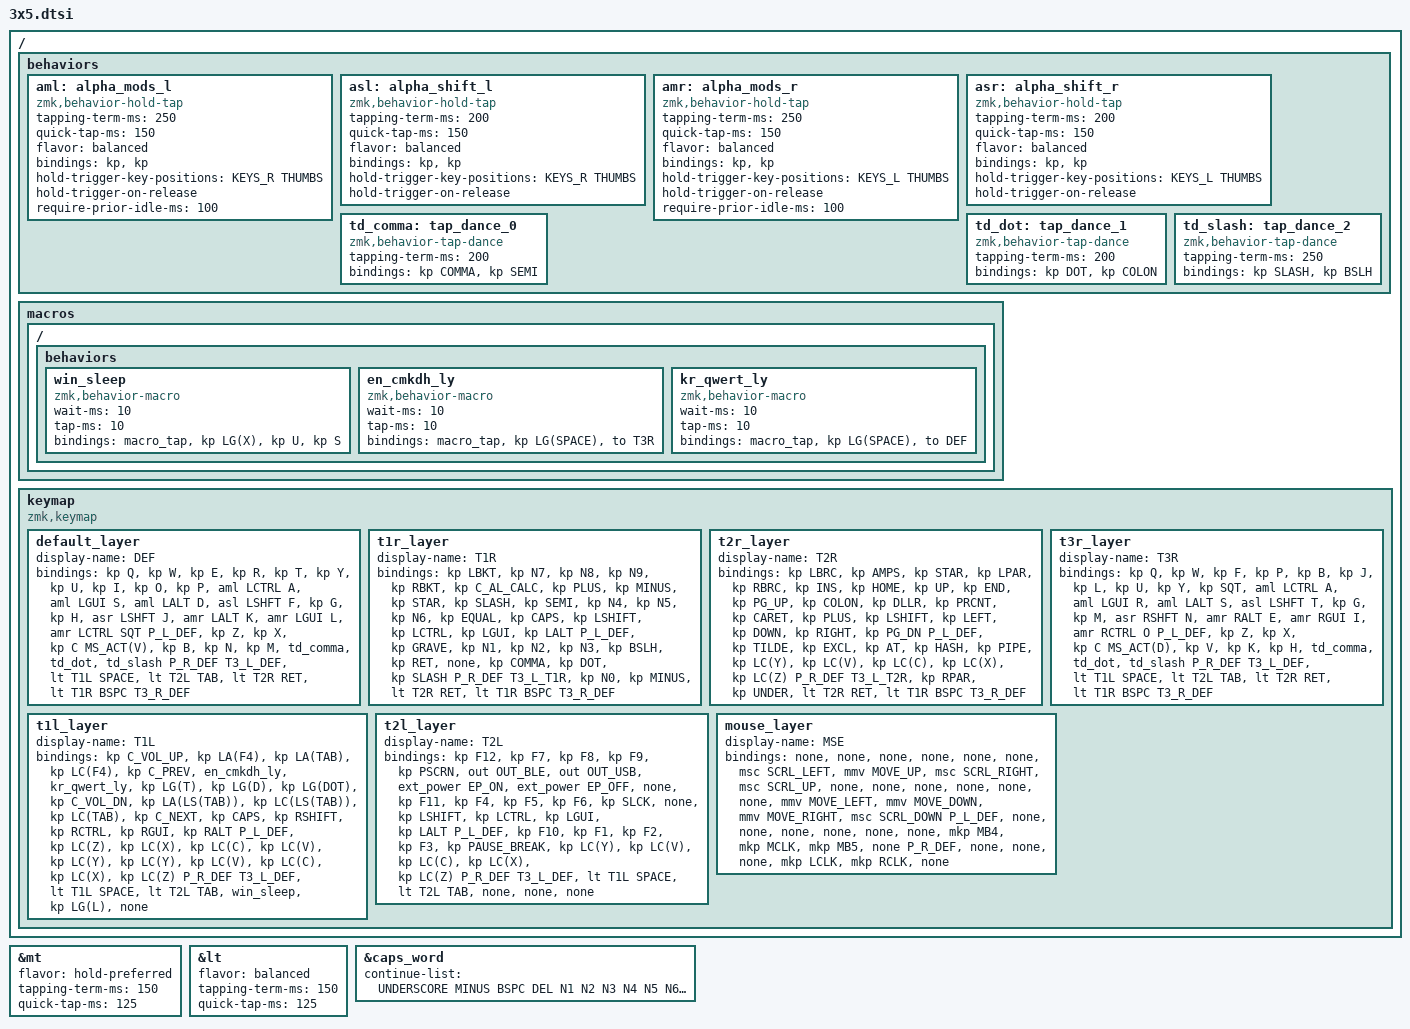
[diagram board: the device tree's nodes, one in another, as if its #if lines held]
#include <behaviors.dtsi>
#include <dt-bindings/zmk/keys.h>
#include <dt-bindings/zmk/bt.h>
#include <dt-bindings/zmk/outputs.h>
#include <dt-bindings/zmk/ext_power.h>


// Layer aliases left thums T0L, right thums T0R
#define DEF 0
#define T1R 1
#define T2R 2
#define T3R 3
#define T1L 4
#define T2L 5
#define MSE 6

// Key position groups and extra key bindings
#ifdef ALPHA_30   /* dropped index and pinkies */
#    define KEYS_L 0 1 2 3 4 10 11 12 13 14 20 21 22 23 24
#    define KEYS_R 5 6 7 8 9 15 16 17 18 19 25 26 27 28 29
#    define P_L_DEF  /* left pinky        */
#    define P_R_DEF  /* right pinky       */
#    define ALP_XXX
#else
#    define KEYS_L 0 1 2 3 4 10 11 12 13 14 20 21 22 23 24 25
#    define KEYS_R 5 6 7 8 9 15 16 17 18 19 26 27 28 29 30 31
#    define P_L_DEF &kp ESC
#    define P_R_DEF &kp RET
#    define ALP_XXX &none
#endif

#ifdef THREE_THUMBS
#    ifdef ALPHA_30
#        define THUMBS 30 31 32 33 34 35
#    else
#        define THUMBS 32 33 34 35 36 37
#    endif
#    define T3_L_DEF &lt MSE ESC
#    define T3_R_DEF &lt T3R DEL
#    define T3_L_T1R &kp DOT
#    define T3_L_T2R &kp LPAR
#    define T3_XXX   &none
#else
#    ifdef ALPHA_30
#        define THUMBS 30 31 32 33
#    else
#        define THUMBS 32 33 34 35
#    endif
#    define T3_L_DEF
#    define T3_R_DEF
#    define T3_L_T1R
#    define T3_L_T2R
#    define T3_XXX
#endif

#include "combos.dtsi"

#ifdef MOUSE_KEYS
#    include "mouse.dtsi"
#    define MS_ACT(key) &lt MSE key
#else
#    define MS_ACT(key) &kp key
#endif

&mt {
    flavor = "hold-preferred";
    tapping-term-ms = <150>;
    quick-tap-ms = <125>;
};

&lt {
    flavor = "balanced";
    tapping-term-ms = <150>;
    quick-tap-ms = <125>;
};

&caps_word {
    continue-list = <UNDERSCORE MINUS BSPC DEL N1 N2 N3 N4 N5 N6 N7 N8 N9 N0>;
};

/ {
    behaviors {
        aml: alpha_mods_l {
            compatible = "zmk,behavior-hold-tap";
            #binding-cells = <2>;
            tapping-term-ms = <250>;
            quick-tap-ms = <150>;
            flavor = "balanced";
            bindings = <&kp>, <&kp>;
            hold-trigger-key-positions = <KEYS_R THUMBS>;
            hold-trigger-on-release;
            require-prior-idle-ms = <100>;
        };
        asl: alpha_shift_l {
            compatible = "zmk,behavior-hold-tap";
            #binding-cells = <2>;
            tapping-term-ms = <200>;
            quick-tap-ms = <150>;
            flavor = "balanced";
            bindings = <&kp>, <&kp>;
            hold-trigger-key-positions = <KEYS_R THUMBS>;
            hold-trigger-on-release;
        };
        amr: alpha_mods_r {
            compatible = "zmk,behavior-hold-tap";
            #binding-cells = <2>;
            tapping-term-ms = <250>;
            quick-tap-ms = <150>;
            flavor = "balanced";
            bindings = <&kp>, <&kp>;
            hold-trigger-key-positions = <KEYS_L THUMBS>;
            hold-trigger-on-release;
            require-prior-idle-ms = <100>;
        };
        asr: alpha_shift_r {
            compatible = "zmk,behavior-hold-tap";
            #binding-cells = <2>;
            tapping-term-ms = <200>;
            quick-tap-ms = <150>;
            flavor = "balanced";
            bindings = <&kp>, <&kp>;
            hold-trigger-key-positions = <KEYS_L THUMBS>;
            hold-trigger-on-release;
        };

        td_comma: tap_dance_0 {
            compatible = "zmk,behavior-tap-dance";
            #binding-cells = <0>;
            tapping-term-ms = <200>;
            bindings = <&kp COMMA>,
                       <&kp SEMI>;
        };
        td_dot: tap_dance_1 {
            compatible = "zmk,behavior-tap-dance";
            #binding-cells = <0>;
            tapping-term-ms = <200>;
            bindings = <&kp DOT>,
                       <&kp COLON>;
        };
        td_slash: tap_dance_2 {
            compatible = "zmk,behavior-tap-dance";
            #binding-cells = <0>;
            tapping-term-ms = <250>;
            bindings = <&kp SLASH>,
                       <&kp BSLH>;
        };
    };

     macros {
        ZMK_MACRO(win_sleep,
            wait-ms = <10>;
            tap-ms = <10>;
            bindings
                = <&macro_tap &kp LG(X) &kp U &kp S>;
        )
        ZMK_MACRO(en_cmkdh_ly,
            wait-ms = <10>;
            tap-ms = <10>;
            bindings
                = <&macro_tap &kp LG(SPACE) &to T3R>;
        )
        ZMK_MACRO(kr_qwert_ly,
            wait-ms = <10>;
            tap-ms = <10>;
            bindings
                = <&macro_tap &kp LG(SPACE) &to DEF>;
        )
    };

    keymap {
        compatible = "zmk,keymap";

        default_layer {
            display-name = "DEF";
            bindings = <
//     ╭─────────────┬─────────────┬─────────────┬─────────────┬─────────────╮   ╭─────────────┬─────────────┬─────────────┬─────────────┬─────────────╮
         &kp Q         &kp W         &kp E         &kp R         &kp T             &kp Y         &kp U         &kp I         &kp O         &kp P
//     ├─────────────┼─────────────┼─────────────┼─────────────┼─────────────┤   ├─────────────┼─────────────┼─────────────┼─────────────┼─────────────┤
         &aml LCTRL A  &aml LGUI S   &aml LALT D   &asl LSHFT F  &kp G             &kp H         &asr LSHFT J  &amr LALT K   &amr LGUI L   &amr LCTRL SQT
//     ├─────────────┼─────────────┼─────────────┼─────────────┼─────────────┤   ├─────────────┼─────────────┼─────────────┼─────────────┼─────────────┤
P_L_DEF  &kp Z         &kp X         &kp C         MS_ACT(V)     &kp B             &kp N         &kp M         &td_comma     &td_dot       &td_slash    P_R_DEF
//     ╰─────────────┴─────────────┴─────────────┼─────────────┼─────────────┤   ├─────────────┼─────────────┼─────────────┴─────────────┴─────────────╯
                                     T3_L_DEF      &lt T1L SPACE &lt T2L TAB       &lt T2R RET   &lt T1R BSPC  T3_R_DEF
//                                               ╰─────────────┴─────────────╯   ╰─────────────┴─────────────╯
            >;
        };

       t1r_layer {
            display-name = "T1R";  // num; calc+mod
            bindings = <
//     ╭─────────────┬─────────────┬─────────────┬─────────────┬─────────────╮   ╭─────────────┬─────────────┬─────────────┬─────────────┬─────────────╮
         &kp LBKT      &kp N7        &kp N8        &kp N9        &kp RBKT          &kp C_AL_CALC &kp PLUS      &kp MINUS     &kp STAR      &kp SLASH
//     ├─────────────┼─────────────┼─────────────┼─────────────┼─────────────┤   ├─────────────┼─────────────┼─────────────┼─────────────┼─────────────┤
         &kp SEMI      &kp N4        &kp N5        &kp N6        &kp EQUAL         &kp CAPS      &kp LSHIFT    &kp LCTRL     &kp LGUI      &kp LALT
//     ├─────────────┼─────────────┼─────────────┼─────────────┼─────────────┤   ├─────────────┼─────────────┼─────────────┼─────────────┼─────────────┤
P_L_DEF  &kp GRAVE     &kp N1        &kp N2        &kp N3        &kp BSLH          &kp RET       &none         &kp COMMA      &kp DOT      &kp SLASH    P_R_DEF
//     ╰─────────────┴─────────────┴─────────────┼─────────────┼─────────────┤   ├─────────────┼─────────────┼─────────────┴─────────────┴─────────────╯
                                     T3_L_T1R      &kp N0        &kp MINUS         &lt T2R RET   &lt T1R BSPC  T3_R_DEF
//                                               ╰─────────────┴─────────────╯   ╰─────────────┴─────────────╯
            >;
        };

       t2r_layer {
            display-name = "T2R";  // sym; nav
            bindings = <
//     ╭─────────────┬─────────────┬─────────────┬─────────────┬─────────────╮   ╭─────────────┬─────────────┬─────────────┬─────────────┬─────────────╮
         &kp LBRC      &kp AMPS      &kp STAR      &kp LPAR      &kp RBRC          &kp INS       &kp HOME      &kp UP        &kp END       &kp PG_UP
//     ├─────────────┼─────────────┼─────────────┼─────────────┼─────────────┤   ├─────────────┼─────────────┼─────────────┼─────────────┼─────────────┤
         &kp COLON     &kp DLLR      &kp PRCNT     &kp CARET     &kp PLUS          &kp LSHIFT    &kp LEFT      &kp DOWN      &kp RIGHT     &kp PG_DN
//     ├─────────────┼─────────────┼─────────────┼─────────────┼─────────────┤   ├─────────────┼─────────────┼─────────────┼─────────────┼─────────────┤
P_L_DEF  &kp TILDE     &kp EXCL      &kp AT        &kp HASH      &kp PIPE          &kp LC(Y)     &kp LC(V)     &kp LC(C)     &kp LC(X)     &kp LC(Z)    P_R_DEF
//     ╰─────────────┴─────────────┴─────────────┼─────────────┼─────────────┤   ├─────────────┼─────────────┼─────────────┴─────────────┴─────────────╯
                                     T3_L_T2R      &kp RPAR      &kp UNDER         &lt T2R RET   &lt T1R BSPC  T3_R_DEF
//                                               ╰─────────────┴─────────────╯   ╰─────────────┴─────────────╯
            >;
        };

        t3r_layer {
            display-name = "T3R";  // colmakdh
            bindings = <
//     ╭─────────────┬─────────────┬─────────────┬─────────────┬─────────────╮   ╭─────────────┬─────────────┬─────────────┬─────────────┬─────────────╮
         &kp Q         &kp W         &kp F         &kp P         &kp B             &kp J         &kp L         &kp U         &kp Y         &kp SQT
//     ├─────────────┼─────────────┼─────────────┼─────────────┼─────────────┤   ├─────────────┼─────────────┼─────────────┼─────────────┼─────────────┤
         &aml LCTRL A  &aml LGUI R   &aml LALT S   &asl LSHFT T  &kp G             &kp M         &asr RSHFT N  &amr RALT E   &amr RGUI I   &amr RCTRL O
//     ├─────────────┼─────────────┼─────────────┼─────────────┼─────────────┤   ├─────────────┼─────────────┼─────────────┼─────────────┼─────────────┤
P_L_DEF  &kp Z         &kp X         &kp C         MS_ACT(D)     &kp V             &kp K         &kp H         &td_comma     &td_dot       &td_slash    P_R_DEF
//     ╰─────────────┴─────────────┴─────────────┼─────────────┼─────────────┤   ├─────────────┼─────────────┼─────────────┴─────────────┴─────────────╯
                                     T3_L_DEF      &lt T1L SPACE &lt T2L TAB       &lt T2R RET   &lt T1R BSPC  T3_R_DEF
//                                               ╰─────────────┴─────────────╯   ╰─────────────┴─────────────╯
            >;
        };

        t1l_layer {
            display-name = "T1L";  // xxx
            bindings = <
//     ╭─────────────┬─────────────┬─────────────┬─────────────┬─────────────╮   ╭─────────────┬─────────────┬─────────────┬─────────────┬─────────────╮
         &kp C_VOL_UP  &kp LA(F4)    &kp LA(TAB)   &kp LC(F4)    &kp C_PREV        &en_cmkdh_ly  &kr_qwert_ly  &kp LG(T)     &kp LG(D)     &kp LG(DOT)
//     ├─────────────┼─────────────┼─────────────┼─────────────┼─────────────┤   ├─────────────┼─────────────┼─────────────┼─────────────┼─────────────┤
         &kp C_VOL_DN  &kp LA(LS(TAB)) &kp LC(LS(TAB)) &kp LC(TAB) &kp C_NEXT      &kp CAPS      &kp RSHIFT    &kp RCTRL     &kp RGUI      &kp RALT
//     ├─────────────┼─────────────┼─────────────┼─────────────┼─────────────┤   ├─────────────┼─────────────┼─────────────┼─────────────┼─────────────┤
P_L_DEF  &kp LC(Z)     &kp LC(X)     &kp LC(C)     &kp LC(V)     &kp LC(Y)         &kp LC(Y)     &kp LC(V)     &kp LC(C)     &kp LC(X)     &kp LC(Z)    P_R_DEF
//     ╰─────────────┴─────────────┴─────────────┼─────────────┼─────────────┤   ├─────────────┼─────────────┼─────────────┴─────────────┴─────────────╯
                                     T3_L_DEF      &lt T1L SPACE &lt T2L TAB       &win_sleep    &kp LG(L)     &none
//                                               ╰─────────────┴─────────────╯   ╰─────────────┴─────────────╯
            >;
        };

        t2l_layer {
            display-name = "T2L";  // fun; kbsys+mod
            bindings = <
//     ╭─────────────┬─────────────┬─────────────┬─────────────┬─────────────╮   ╭─────────────┬─────────────┬─────────────┬─────────────┬─────────────╮
         &kp F12       &kp F7        &kp F8        &kp F9        &kp PSCRN         &out OUT_BLE  &out OUT_USB &ext_power EP_ON &ext_power EP_OFF &none
//     ├─────────────┼─────────────┼─────────────┼─────────────┼─────────────┤   ├─────────────┼─────────────┼─────────────┼─────────────┼─────────────┤
         &kp F11       &kp F4        &kp F5        &kp F6        &kp SLCK          &none         &kp LSHIFT    &kp LCTRL     &kp LGUI      &kp LALT
//     ├─────────────┼─────────────┼─────────────┼─────────────┼─────────────┤   ├─────────────┼─────────────┼─────────────┼─────────────┼─────────────┤
P_L_DEF  &kp F10       &kp F1        &kp F2        &kp F3        &kp PAUSE_BREAK   &kp LC(Y)     &kp LC(V)     &kp LC(C)     &kp LC(X)     &kp LC(Z)    P_R_DEF
//     ╰─────────────┴─────────────┴─────────────┼─────────────┼─────────────┤   ├─────────────┼─────────────┼─────────────┴─────────────┴─────────────╯
                                     T3_L_DEF      &lt T1L SPACE &lt T2L TAB       &none         &none         &none
//                                               ╰─────────────┴─────────────╯   ╰─────────────┴─────────────╯
            >;
        };

#ifdef MOUSE_KEYS
        mouse_layer {
            display-name = "MSE";    // T3L
            bindings = <
//     ╭─────────────┬─────────────┬─────────────┬─────────────┬─────────────╮   ╭─────────────┬─────────────┬─────────────┬─────────────┬─────────────╮
         &none         &none         &none         &none         &none             &none        &msc SCRL_LEFT &mmv MOVE_UP  &msc SCRL_RIGHT &msc SCRL_UP
//     ├─────────────┼─────────────┼─────────────┼─────────────┼─────────────┤   ├─────────────┼─────────────┼─────────────┼─────────────┼─────────────┤
         &none         &none         &none         &none         &none             &none       &mmv MOVE_LEFT &mmv MOVE_DOWN &mmv MOVE_RIGHT &msc SCRL_DOWN
//     ├─────────────┼─────────────┼─────────────┼─────────────┼─────────────┤   ├─────────────┼─────────────┼─────────────┼─────────────┼─────────────┤
P_L_DEF  &none         &none         &none         &none         &none             &none         &mkp MB4      &mkp MCLK     &mkp MB5      &none        P_R_DEF
//     ╰─────────────┴─────────────┴─────────────┼─────────────┼─────────────┤   ├─────────────┼─────────────┼─────────────┴─────────────┴─────────────╯
                                     &none         &none         &none             &mkp LCLK     &mkp RCLK     &none
//                                               ╰─────────────┴─────────────╯   ╰─────────────┴─────────────╯
            >;
        };
#endif

    };
};
